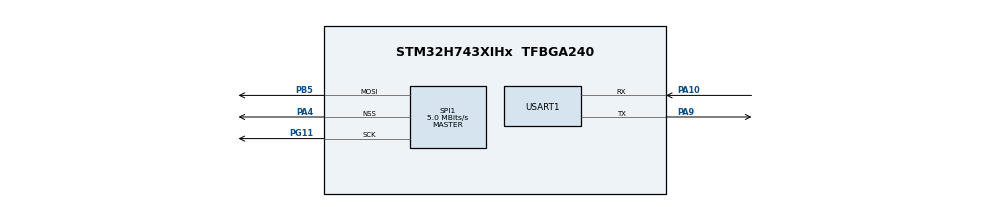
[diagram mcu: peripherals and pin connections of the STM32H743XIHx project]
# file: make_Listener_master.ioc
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CORTEX_M7.default_mode_Activation=1
Mcu.Family=STM32H7
Mcu.Name=STM32H743XIHx
Mcu.Package=TFBGA240
NVIC.PriorityGroup=NVIC_PRIORITYGROUP_4
NVIC.SPI1_IRQn=true\:0\:0\:false\:false\:true\:true\:true\:true
PA10.Mode=Asynchronous
PA10.Signal=USART1_RX
PA4.Mode=NSS_Signal_Hard_Output
PA4.Signal=SPI1_NSS
PA9.Mode=Asynchronous
PA9.Signal=USART1_TX
PB5.Mode=TX_Only_Simplex_Unidirect_Master
PB5.Signal=SPI1_MOSI
PG11.Mode=TX_Only_Simplex_Unidirect_Master
PG11.Signal=SPI1_SCK
PH0-OSC_IN\ (PH0).Mode=HSE-External-Oscillator
PH0-OSC_IN\ (PH0).Signal=RCC_OSC_IN
PH1-OSC_OUT\ (PH1).Mode=HSE-External-Oscillator
PH1-OSC_OUT\ (PH1).Signal=RCC_OSC_OUT
ProjectManager.HeapSize=0x200
ProjectManager.StackSize=0x400
ProjectManager.TargetToolchain=STM32CubeIDE
RCC.ADCFreq_Value=50390625
RCC.APB1Freq_Value=120000000
RCC.APB2Freq_Value=120000000
RCC.APB3Freq_Value=120000000
RCC.APB4Freq_Value=120000000
RCC.CortexFreq_Value=480000000
RCC.D1PPRE=RCC_APB3_DIV2
RCC.D2PPRE1=RCC_APB1_DIV2
RCC.D2PPRE2=RCC_APB2_DIV2
RCC.D3PPRE=RCC_APB4_DIV2
RCC.DIVM1=5
RCC.DIVM3=5
RCC.DIVN1=192
RCC.DIVN3=150
RCC.DIVP3=75
RCC.HCLKFreq_Value=240000000
RCC.HPRE=RCC_HCLK_DIV2
RCC.HSE_VALUE=25000000
RCC.PLL3FRACN=0
RCC.PLLFRACN=0
RCC.PLLSourceVirtual=RCC_PLLSOURCE_HSE
RCC.SPI123CLockSelection=RCC_SPI123CLKSOURCE_PLL3
RCC.SYSCLKFreq_VALUE=480000000
RCC.SYSCLKSource=RCC_SYSCLKSOURCE_PLLCLK
RCC.USBFreq_Value=480000000
SPI1.BaudRatePrescaler=SPI_BAUDRATEPRESCALER_2
SPI1.CalculateBaudRate=5.0 MBits/s
SPI1.DataSize=SPI_DATASIZE_8BIT
SPI1.Direction=SPI_DIRECTION_2LINES_TXONLY
SPI1.Mode=SPI_MODE_MASTER
SPI1.NSSPMode=SPI_NSS_PULSE_DISABLE
SPI1.VirtualNSS=VM_NSSHARD
SPI1.VirtualType=VM_MASTER
USART1.VirtualMode-Asynchronous=VM_ASYNC
VP_MEMORYMAP_VS_MEMORYMAP.Mode=CurAppReg
board=custom

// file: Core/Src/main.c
/* USER CODE BEGIN Header */
/**
  ******************************************************************************
  * @file           : main.c
  * @brief          : Main program body
  ******************************************************************************
  * @attention
  *
  * Copyright (c) 2025 STMicroelectronics.
  * All rights reserved.
  *
  * This software is licensed under terms that can be found in the LICENSE file
  * in the root directory of this software component.
  * If no LICENSE file comes with this software, it is provided AS-IS.
  *
  ******************************************************************************
  */
/* USER CODE END Header */
#include "main.h"
#include "spi.h"
#include "usart.h"
#include "gpio.h"

/* USER CODE BEGIN Includes */
#include <stdio.h>
#include "string.h"
/* USER CODE END Includes */

void SystemClock_Config(void);
static void MPU_Config(void);

int main(void)
{

  /* USER CODE BEGIN 1 */

	uint8_t tx_data[4] = {0xaa, 0x55, 0xaa, 0x55};
	uint8_t i = 0;

  /* USER CODE END 1 */

  /* MPU Configuration--------------------------------------------------------*/
  MPU_Config();

  /* MCU Configuration--------------------------------------------------------*/

  /* Reset of all peripherals, Initializes the Flash interface and the Systick. */
  HAL_Init();

  /* Configure the system clock */
  SystemClock_Config();

  /* Initialize all configured peripherals */
  MX_GPIO_Init();
  MX_SPI1_Init();
  MX_USART1_UART_Init();

  /* Infinite loop */
  /* USER CODE BEGIN WHILE */
  while (1)
  {
	  if(i != 4){
		  HAL_StatusTypeDef result = HAL_SPI_Transmit(&hspi1, &tx_data[i], 1, 1000);
          if(result == HAL_OK){
			  char str[50];
			  sprintf(str,"SuCCEss, rx_buffer[%d] = %d \n", i, tx_data[i]);
			  HAL_UART_Transmit(&huart1, (uint8_t *)str, strlen(str), 1000);
          }

			  HAL_Delay(100);
		  i++;
	  }
	  else {
		  i = 0;
	  }
//	  HAL_Delay(100);
    /* USER CODE END WHILE */

  }
}

void SystemClock_Config(void)
{
  RCC_OscInitTypeDef RCC_OscInitStruct = {0};
  RCC_ClkInitTypeDef RCC_ClkInitStruct = {0};

  /** Supply configuration update enable
  */
  HAL_PWREx_ConfigSupply(PWR_LDO_SUPPLY);

  /** Configure the main internal regulator output voltage
  */
  __HAL_PWR_VOLTAGESCALING_CONFIG(PWR_REGULATOR_VOLTAGE_SCALE0);

  while(!__HAL_PWR_GET_FLAG(PWR_FLAG_VOSRDY)) {}

  /** Initializes the RCC Oscillators according to the specified parameters
  * in the RCC_OscInitTypeDef structure.
  */
  RCC_OscInitStruct.OscillatorType = RCC_OSCILLATORTYPE_HSE;
  RCC_OscInitStruct.HSEState = RCC_HSE_ON;
  RCC_OscInitStruct.PLL.PLLState = RCC_PLL_ON;
  RCC_OscInitStruct.PLL.PLLSource = RCC_PLLSOURCE_HSE;
  RCC_OscInitStruct.PLL.PLLM = 5;
  RCC_OscInitStruct.PLL.PLLN = 192;
  RCC_OscInitStruct.PLL.PLLP = 2;
  RCC_OscInitStruct.PLL.PLLQ = 2;
  RCC_OscInitStruct.PLL.PLLR = 2;
  RCC_OscInitStruct.PLL.PLLRGE = RCC_PLL1VCIRANGE_2;
  RCC_OscInitStruct.PLL.PLLVCOSEL = RCC_PLL1VCOWIDE;
  RCC_OscInitStruct.PLL.PLLFRACN = 0;
  if (HAL_RCC_OscConfig(&RCC_OscInitStruct) != HAL_OK)
  {
    Error_Handler();
  }

  /** Initializes the CPU, AHB and APB buses clocks
  */
  RCC_ClkInitStruct.ClockType = RCC_CLOCKTYPE_HCLK|RCC_CLOCKTYPE_SYSCLK
                              |RCC_CLOCKTYPE_PCLK1|RCC_CLOCKTYPE_PCLK2
                              |RCC_CLOCKTYPE_D3PCLK1|RCC_CLOCKTYPE_D1PCLK1;
  RCC_ClkInitStruct.SYSCLKSource = RCC_SYSCLKSOURCE_PLLCLK;
  RCC_ClkInitStruct.SYSCLKDivider = RCC_SYSCLK_DIV1;
  RCC_ClkInitStruct.AHBCLKDivider = RCC_HCLK_DIV2;
  RCC_ClkInitStruct.APB3CLKDivider = RCC_APB3_DIV2;
  RCC_ClkInitStruct.APB1CLKDivider = RCC_APB1_DIV2;
  RCC_ClkInitStruct.APB2CLKDivider = RCC_APB2_DIV2;
  RCC_ClkInitStruct.APB4CLKDivider = RCC_APB4_DIV2;

  if (HAL_RCC_ClockConfig(&RCC_ClkInitStruct, FLASH_LATENCY_4) != HAL_OK)
  {
    Error_Handler();
  }
}

 /* MPU Configuration */

void MPU_Config(void)
{
  MPU_Region_InitTypeDef MPU_InitStruct = {0};

  /* Disables the MPU */
  HAL_MPU_Disable();

  /** Initializes and configures the Region and the memory to be protected
  */
  MPU_InitStruct.Enable = MPU_REGION_ENABLE;
  MPU_InitStruct.Number = MPU_REGION_NUMBER0;
  MPU_InitStruct.BaseAddress = 0x0;
  MPU_InitStruct.Size = MPU_REGION_SIZE_4GB;
  MPU_InitStruct.SubRegionDisable = 0x87;
  MPU_InitStruct.TypeExtField = MPU_TEX_LEVEL0;
  MPU_InitStruct.AccessPermission = MPU_REGION_NO_ACCESS;
  MPU_InitStruct.DisableExec = MPU_INSTRUCTION_ACCESS_DISABLE;
  MPU_InitStruct.IsShareable = MPU_ACCESS_SHAREABLE;
  MPU_InitStruct.IsCacheable = MPU_ACCESS_NOT_CACHEABLE;
  MPU_InitStruct.IsBufferable = MPU_ACCESS_NOT_BUFFERABLE;

  HAL_MPU_ConfigRegion(&MPU_InitStruct);
  /* Enables the MPU */
  HAL_MPU_Enable(MPU_PRIVILEGED_DEFAULT);

}

void Error_Handler(void)
{
  __disable_irq();
  while (1)
  {
  }
}
